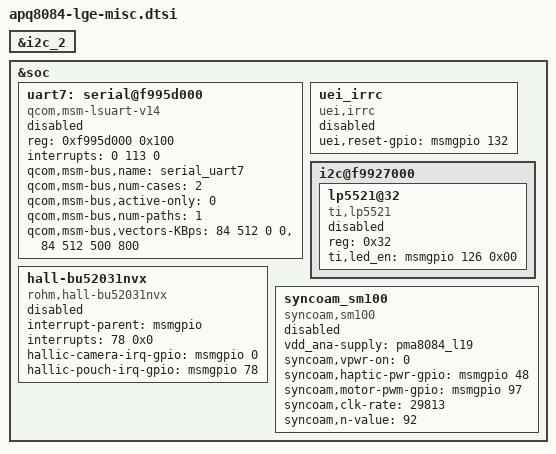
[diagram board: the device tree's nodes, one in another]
/* Copyright (c) 2012, Code Aurora Forum. All rights reserved.
 *
 * This program is free software; you can redistribute it and/or modify
 * it under the terms of the GNU General Public License version 2 and
 * only version 2 as published by the Free Software Foundation.
 *
 * This program is distributed in the hope that it will be useful,
 * but WITHOUT ANY WARRANTY; without even the implied warranty of
 * MERCHANTABILITY or FITNESS FOR A PARTICULAR PURPOSE.  See the
 * GNU General Public License for more details.
 */

&i2c_2 {
	/delete-node/ isa1200;
};

&soc {

	uart7: serial@f995d000 {
		compatible = "qcom,msm-lsuart-v14";
		reg = <0xf995d000 0x100>;
		interrupts = <0 113 0>;
		status = "disable";

		qcom,msm-bus,name = "serial_uart7";
		qcom,msm-bus,num-cases = <2>;
		qcom,msm-bus,active-only = <0>;
		qcom,msm-bus,num-paths = <1>;
		qcom,msm-bus,vectors-KBps =
			<84 512 0 0>,
			<84 512 500 800>;
		};

	uei_irrc {
		status = "disable";
		compatible = "uei,irrc";
		uei,reset-gpio = <&msmgpio 132 0x00>;
	};

	i2c@f9927000 {
		lp5521@32 {
			compatible = "ti,lp5521";
			status = "disable";
			reg = <0x32>;
			ti,led_en = <&msmgpio 126 0x00>;
		};
	};

	hall-bu52031nvx {
		status = "disable";
		compatible = "rohm,hall-bu52031nvx";
		interrupt-parent = <&msmgpio>;
		interrupts = <78 0x0>;
		hallic-camera-irq-gpio = <&msmgpio 0 0x00>;
		hallic-pouch-irq-gpio = <&msmgpio 78 0x00>;
	};

	syncoam_sm100 {
		compatible = "syncoam,sm100";
		status = "disable";
		vdd_ana-supply = <&pma8084_l19>;
		syncoam,vpwr-on = <0>;
		syncoam,haptic-pwr-gpio = <&msmgpio 48 0x00>;
		syncoam,motor-pwm-gpio = <&msmgpio 97 0x00>;
		syncoam,clk-rate = <29813>;
		syncoam,n-value = <92>;
	};
};
